# DP32G030 register map
File version: 1.0
CPU: CM0 r0p0, little endian, no MPU, no FPU, 4 interrupt priority bits
Registers are 32-bit, read-write, reset 0x0 unless marked. A register's access mark holds for its fields unless they carry their own. Offsets are from the block's base; [hi:lo] are bit positions.

## SPI0 — SPI0 unit
Base 0x400B8000
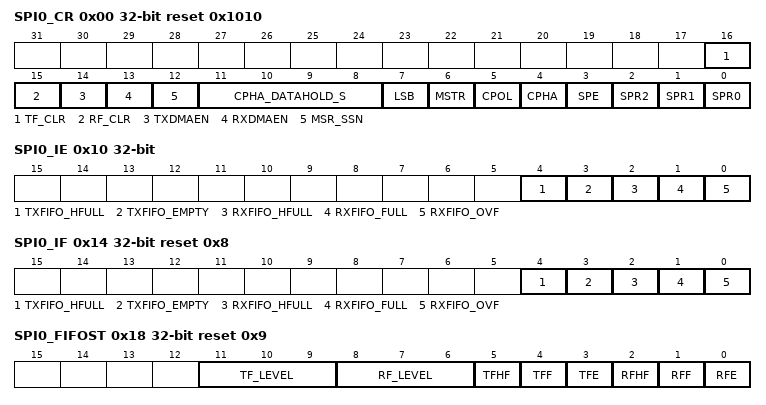
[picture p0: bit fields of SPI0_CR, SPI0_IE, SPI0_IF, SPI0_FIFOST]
0x00 SPI0_CR reset 0x1010 — SPI control register
  [16] TF_CLR write-1-clears — Send FIFO Clear Bit Software Write 1 Clear Transmit FIFO, Hardware Auto-Clear
  [15] RF_CLR write-1-clears — Receive FIFO Clear Bit Software Write 1 Clear Receive FIFO, Hardware Auto-Clear
  [14] TXDMAEN — Send DMA control enable bit 1: Indicates the transmit data register for DMA operation SPI. 0: Indicates that the CPU operates the SPI transmit data register.
  [13] RXDMAEN — Receive DMA control enable bit 1: Indicates the receive data register for DMA operation SPI. 0: Indicates that the CPU operates the receive data register of the SPI.
  [12] MSR_SSN — SSN output in master mode, default output 1 This register is only valid in master mode
  [11:8] CPHA_DATAHOLD_S — Data Hold Time Configuration Register when CPHA is 1 in Slave Mode 0000: 1 pclk 0001: 2 pclk ...... 1111: 16 pclk
  [7] LSB — Data transfer sequence selection 0: MSB 1: LSB
  [6] MSTR — Master-Slave mode selection 0 = SPI system configured in slave mode 1 = SPI system configured as master device mode
  [5] CPOL — Clock Polarity Selection 0 = Serial clock idle state is low, active level is high 1 = Serial clock idle state is high, active level is low
  [4] CPHA — Clock phase selection 0 = sample data at the first edge of the serial clock jump 1 = Sample data on the second edge of the serial clock jump
  [3] SPE — SPI System Enable 0 = SPI system shutdown 1 = SPI system enable
  [2] SPR2 — SPI baud rate select bit 2
  [1] SPR1 — SPI baud rate select bit 1
  [0] SPR0 — SPI baud rate select bit 0
0x04 SPI0_WDR — SPI write data register
  [7:0] SPIWDR — SPI writes the data to be sent to the transmit FIFO through the SPIWDR register. When the data is ready to be sent, the shift register reads the transmit FIFO directly to send the data.
0x08 SPI0_RDR ro — SPI read data register
  [7:0] SPIRDR — SPI reads the received data through the SPIRDR register. The shift register stores the data in the receive FIFO after each transmission is completed and reads the data in the receive FIFO through the SPIRDR register.
0x10 SPI0_IE — SPI interrupt enable register
  [4] TXFIFO_HFULL — Send FIFO half-full interrupt enable
  [3] TXFIFO_EMPTY — Transmit FIFO air-break enable
  [2] RXFIFO_HFULL — Receive FIFO half-full interrupt enable
  [1] RXFIFO_FULL — Receive FIFO full interrupt enable
  [0] RXFIFO_OVF — Receive FIFO overflow interrupt enable
0x14 SPI0_IF reset 0x8 — SPI Interrupt Status Register
  [4] TXFIFO_HFULL write-1-clears — Send FIFO half-full Flag Write 1 Clear
  [3] TXFIFO_EMPTY write-1-clears — Send FIFO Empty Flag Write 1 Clear
  [2] RXFIFO_HFULL write-1-clears — Receive FIFO half-full flag write 1 clear
  [1] RXFIFO_FULL write-1-clears — Receive FIFO full flag write 1 clear
  [0] RXFIFO_OVF write-1-clears — Receive FIFO Overflow Flag Write 1 Clear Note: Data after overflow will be discarded.
0x18 SPI0_FIFOST ro reset 0x9 — SPI FIFO status register
  [11:9] TF_LEVEL — Send FIFO water level status 000: If the FIFO is not full, it means that there is 0 data in the FIFO, and if it is full, it means that there is 0 data in the FIFO. 8 data; 001: Indicates that the FIFO has 1 data; 010: Indicates that the FIFO has 2 data; 011: Indicates that the FIFO has 3 data; 100: Indicates that the FIFO has 4 data; 101: Indicates that the FIFO has 5 data; 110: Indicates that the FIFO has 6 data; 111: Indicates that the FIFO has 7 data;
  [8:6] RF_LEVEL — Receive FIFO water level status 000: If the FIFO is not full, it means that there is 0 data in the FIFO, and if it is full, it means that there is 0 data in the FIFO. 8 data; 001: Indicates that the FIFO has 1 data; 010: Indicates that the FIFO has 2 data; 011: Indicates that the FIFO has 3 data; 100: Indicates that the FIFO has 4 data; 101: Indicates that the FIFO has 5 data; 110: Indicates that the FIFO has 6 data; 111: Indicates that the FIFO has 7 data;
  [5] TFHF — Send FIFO half full flag
  [4] TFF — Send FIFO full flag
  [3] TFE — Send FIFO Empty Flag
  [2] RFHF — Receive FIFO half-full flag
  [1] RFF — Receive FIFO full flag
  [0] RFE — Receive FIFO empty flag

## SPI1 — SPI1 unit
Base 0x400B8800
Registers as SPI0 (with SPI0 read as SPI1).
